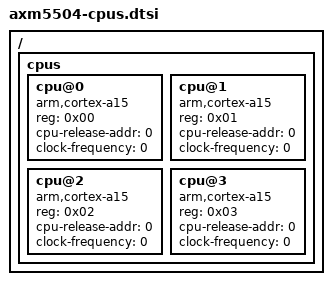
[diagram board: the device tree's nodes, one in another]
/*
 * arch/arm/boot/dts/axm5504-cpus.dtsi
 *
 * Copyright (C) 2018 INTEL
 *
 * This program is free software; you can redistribute it and/or modify
 * it under the terms of the GNU General Public License as published by
 * the Free Software Foundation; either version 2 of the License, or
 * (at your option) any later version.
 */

/ {
	cpus {
		#address-cells = <1>;
		#size-cells = <0>;

		cpu@0 {
			device_type = "cpu";
			compatible = "arm,cortex-a15";
			reg = <0x00>;
			cpu-release-addr = <0>; // Fixed by the boot loader
			clock-frequency = <0>;  // Placeholder
		};

		cpu@1 {
			device_type = "cpu";
			compatible = "arm,cortex-a15";
			reg = <0x01>;
			cpu-release-addr = <0>; // Fixed by the boot loader
			clock-frequency = <0>;  // Placeholder
		};

		cpu@2 {
			device_type = "cpu";
			compatible = "arm,cortex-a15";
			reg = <0x02>;
			cpu-release-addr = <0>; // Fixed by the boot loader
			clock-frequency = <0>;  // Placeholder
		};

		cpu@3 {
			device_type = "cpu";
			compatible = "arm,cortex-a15";
			reg = <0x03>;
			cpu-release-addr = <0>; // Fixed by the boot loader
			clock-frequency = <0>;  // Placeholder
		};
	};
};
